# STM32F423xx register map
File version: 1.0
Registers are 32-bit, read-write, reset 0x0 unless marked. A register's access mark holds for its fields unless they carry their own. Offsets are from the block's base; [hi:lo] are bit positions; {n}, {i} and the like mark numbered series; 'fields as' and 'values as' point back to an identical list.

## AES — AES hardware accelerator
Base 0x50060000
0x00 CR — AES control register
0x04 SR — AES status register
0x08 DINR — AES data input register
0x0C DOUTR — AES data output register
{0x10+4i} KEYR{i} (i=0..3) — AES key register {i}
{0x20+4i} IVR{i} (i=0..3) — AES initialization vector register {i}
{0x20+4i} KEYR{i} (i=4..7) — AES key register {i}
{0x40+4i} SUSP{i}R (i=0..7) — AES Suspend register {i}

## RNG
Base 0x50060800
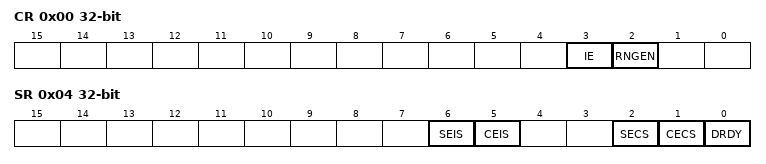
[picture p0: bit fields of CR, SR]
0x00 CR — RNG control register
  [3] IE, [2] RNGEN
0x04 SR — RNG status register
  [6] SEIS, [5] CEIS, [2] SECS, [1] CECS, [0] DRDY
0x08 DR — RNG data register

## FSMC_Bank1 — Flexible Static Memory Controller
Base 0xA0000000
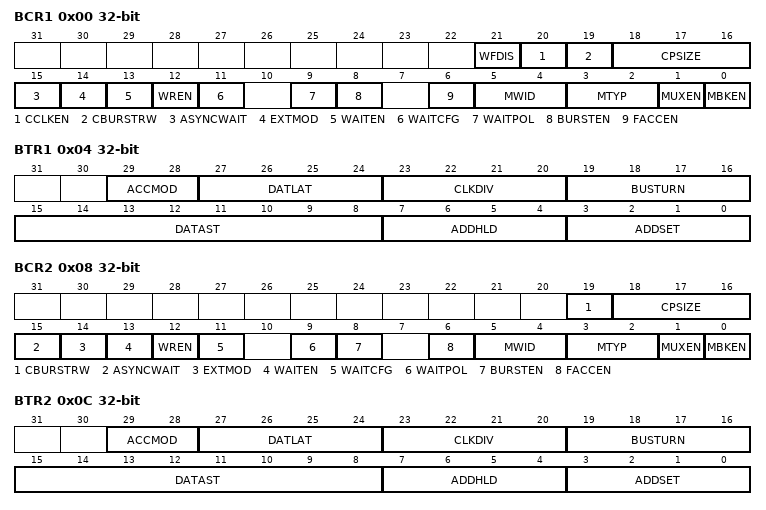
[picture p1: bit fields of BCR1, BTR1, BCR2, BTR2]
0x00 BCR1 — NOR/PSRAM chip-select control register(BCR) and chip-select timing register(BTR)
  [21] WFDIS — Write FIFO Disable
  [20] CCLKEN — Continuous clock enable
  [19] CBURSTRW — Write burst enable
  [18:16] CPSIZE — CRAM page size
  [15] ASYNCWAIT — Asynchronous wait
  [14] EXTMOD — Extended mode enable
  [13] WAITEN — Wait enable bit
  [12] WREN — Write enable bit
  [11] WAITCFG — Wait timing configuration
  [9] WAITPOL — Wait signal polarity bit
  [8] BURSTEN — Burst enable bit
  [6] FACCEN — Flash access enable
  [5:4] MWID — MWID[1:0] bits (Memory data bus width)
  [3:2] MTYP — MTYP[1:0] bits (Memory type)
  [1] MUXEN — Address/data multiplexing enable bit
  [0] MBKEN — Memory bank enable bit
0x04 BTR1 — NOR/PSRAM chip-select control register(BCR) and chip-select timing register(BTR)
  [29:28] ACCMOD — ACCMOD[1:0] bits (Access mode)
  [27:24] DATLAT — DATLA[3:0] bits (Data latency)
  [23:20] CLKDIV — CLKDIV[3:0] bits (Clock divide ratio)
  [19:16] BUSTURN — BUSTURN[3:0] bits (Bus turnaround phase duration)
  [15:8] DATAST — DATAST [7:0] bits (Data-phase duration)
  [7:4] ADDHLD — ADDHLD[3:0] bits (Address-hold phase duration)
  [3:0] ADDSET — ADDSET[3:0] bits (Address setup phase duration)
0x08 BCR2 — NOR/PSRAM chip-select control register(BCR) and chip-select timing register(BTR)
  [19] CBURSTRW — Write burst enable
  [18:16] CPSIZE — CRAM page size
  [15] ASYNCWAIT — Asynchronous wait
  [14] EXTMOD — Extended mode enable
  [13] WAITEN — Wait enable bit
  [12] WREN — Write enable bit
  [11] WAITCFG — Wait timing configuration
  [9] WAITPOL — Wait signal polarity bit
  [8] BURSTEN — Burst enable bit
  [6] FACCEN — Flash access enable
  [5:4] MWID — MWID[1:0] bits (Memory data bus width)
  [3:2] MTYP — MTYP[1:0] bits (Memory type)
  [1] MUXEN — Address/data multiplexing enable bit
  [0] MBKEN — Memory bank enable bit
0x0C BTR2 — NOR/PSRAM chip-select control register(BCR) and chip-select timing register(BTR)
  fields as BTR1
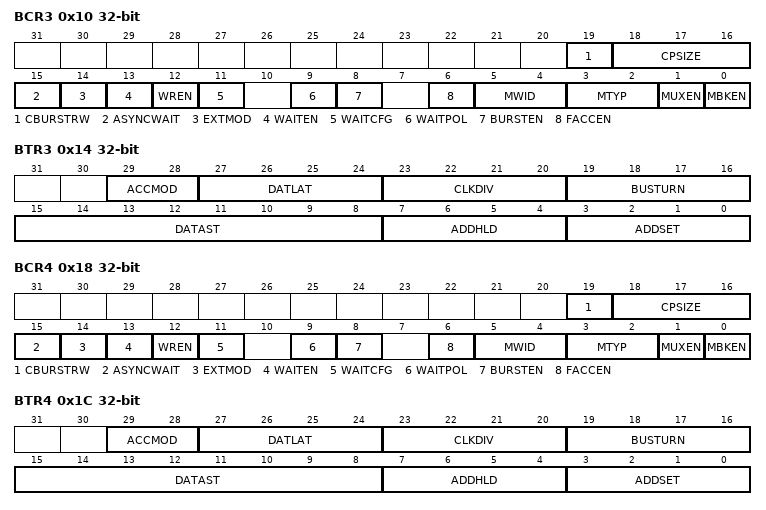
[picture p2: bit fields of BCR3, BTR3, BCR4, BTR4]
0x10 BCR3 — NOR/PSRAM chip-select control register(BCR) and chip-select timing register(BTR)
  fields as BCR2
0x14 BTR3 — NOR/PSRAM chip-select control register(BCR) and chip-select timing register(BTR)
  fields as BTR1
0x18 BCR4 — NOR/PSRAM chip-select control register(BCR) and chip-select timing register(BTR)
  fields as BCR2
0x1C BTR4 — NOR/PSRAM chip-select control register(BCR) and chip-select timing register(BTR)
  fields as BTR1

## FSMC_Bank1E — Flexible Static Memory Controller Bank1E
Base 0xA0000104
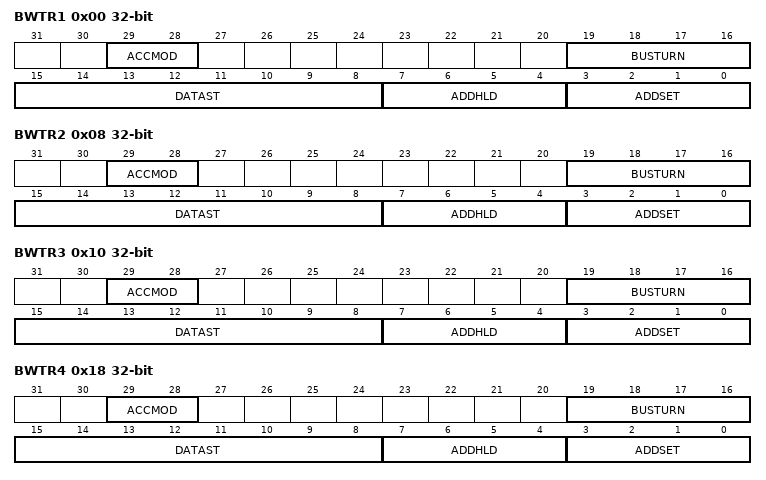
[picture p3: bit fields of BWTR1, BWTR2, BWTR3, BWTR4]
0x00 BWTR1 — NOR/PSRAM write timing registers
  [29:28] ACCMOD — ACCMOD[1:0] bits (Access mode)
  [19:16] BUSTURN — BUSTURN[3:0] bits (Bus turnaround duration)
  [15:8] DATAST — DATAST [7:0] bits (Data-phase duration)
  [7:4] ADDHLD — ADDHLD[3:0] bits (Address-hold phase duration)
  [3:0] ADDSET — ADDSET[3:0] bits (Address setup phase duration)
0x08 BWTR2 — NOR/PSRAM write timing registers
  fields as BWTR1
0x10 BWTR3 — NOR/PSRAM write timing registers
  fields as BWTR1
0x18 BWTR4 — NOR/PSRAM write timing registers
  [29:28] ACCMOD — ACCMOD[1:0] bits (Access mode)
  [19:16] BUSTURN — BUSTURN[3:0] bits (Bus turnaround duration)
  [15:8] DATAST — DATAST [3:0] bits (Data-phase duration)
  [7:4] ADDHLD — ADDHLD[3:0] bits (Address-hold phase duration)
  [3:0] ADDSET — ADDSET[3:0] bits (Address setup phase duration)

## QUADSPI — QUAD Serial Peripheral Interface
Base 0xA0001000
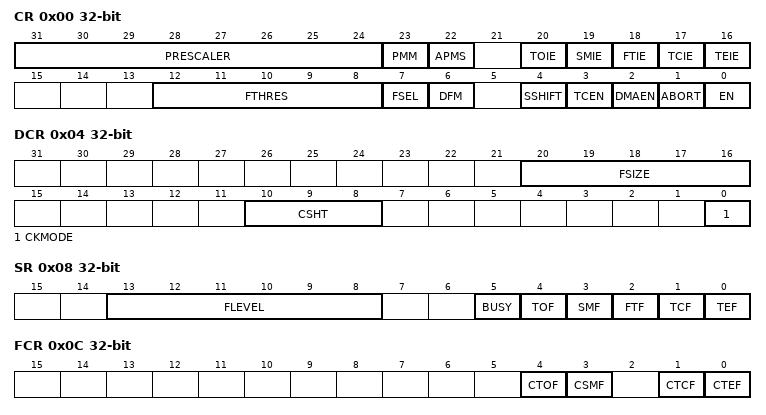
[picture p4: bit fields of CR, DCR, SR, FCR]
0x00 CR — QUADSPI Control register
  [31:24] PRESCALER — PRESCALER[7:0] Clock prescaler
  [23] PMM — Polling Match Mode
  [22] APMS — Bit 1
  [20] TOIE — TimeOut Interrupt Enable
  [19] SMIE — Status Match Interrupt Enable
  [18] FTIE — FIFO Threshold Interrupt Enable
  [17] TCIE — Transfer Complete Interrupt Enable
  [16] TEIE — Transfer Error Interrupt Enable
  [12:8] FTHRES — FTHRES[3:0] FIFO Level
  [7] FSEL — Flash Select
  [6] DFM — Dual Flash Mode
  [4] SSHIFT — SSHIFT Sample Shift
  [3] TCEN — Timeout Counter Enable
  [2] DMAEN — DMA Enable
  [1] ABORT — Abort request
  [0] EN — Enable
0x04 DCR — QUADSPI Device Configuration register
  [20:16] FSIZE — FSIZE[4:0]: Flash Size
  [10:8] CSHT — CSHT[2:0]: ChipSelect High Time
  [0] CKMODE — Mode 0 / Mode 3
0x08 SR — QUADSPI Status register
  [13:8] FLEVEL — FIFO Threshlod Flag
  [5] BUSY
  [4] TOF — Timeout Flag
  [3] SMF — Status Match Flag
  [2] FTF — FIFO Threshlod Flag
  [1] TCF — Transfer Complete Flag
  [0] TEF — Transfer Error Flag
0x0C FCR — QUADSPI Flag Clear register
  [4] CTOF — Clear Timeout Flag
  [3] CSMF — Clear Status Match Flag
  [1] CTCF — Clear Transfer Complete Flag
  [0] CTEF — Clear Transfer Error Flag
0x10 DLR — QUADSPI Data Length register
  [31:0] DL — DL[31:0]: Data Length
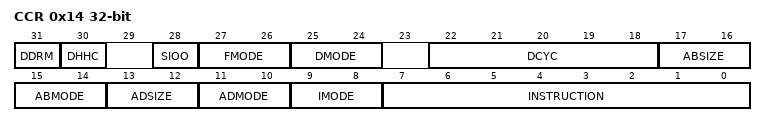
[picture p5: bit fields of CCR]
0x14 CCR — QUADSPI Communication Configuration register
  [31] DDRM — DDRM: Double Data Rate Mode
  [30] DHHC — DHHC: Delay Half Hclk Cycle
  [28] SIOO — SIOO: Send Instruction Only Once Mode
  [27:26] FMODE — FMODE[1:0]: Functional Mode
  [25:24] DMODE — DMODE[1:0]: Data Mode
  [22:18] DCYC — DCYC[4:0]: Dummy Cycles
  [17:16] ABSIZE — ABSIZE[1:0]: Instruction Mode
  [15:14] ABMODE — ABMODE[1:0]: Alternate Bytes Mode
  [13:12] ADSIZE — ADSIZE[1:0]: Address Size
  [11:10] ADMODE — ADMODE[1:0]: Address Mode
  [9:8] IMODE — IMODE[1:0]: Instruction Mode
  [7:0] INSTRUCTION — INSTRUCTION[7:0]: Instruction
0x18 AR — QUADSPI Address register
  [31:0] ADDRESS — ADDRESS[31:0]: Address
0x1C ABR — QUADSPI Alternate Bytes register
  [31:0] ALTERNATE — ALTERNATE[31:0]: Alternate Bytes
0x20 DR — QUADSPI Data register
  [31:0] DATA — DATA[31:0]: Data
0x24 PSMKR — QUADSPI Polling Status Mask register
  [31:0] MASK — MASK[31:0]: Status Mask
0x28 PSMAR — QUADSPI Polling Status Match register
  [31:0] MATCH — MATCH[31:0]: Status Match
0x2C PIR — QUADSPI Polling Interval register
  [15:0] INTERVAL — INTERVAL[15:0]: Polling Interval
0x30 LPTR — QUADSPI Low Power Timeout register
  [15:0] TIMEOUT — TIMEOUT[15:0]: Timeout period

## DBGMCU — Debug MCU
Base 0xE0042000
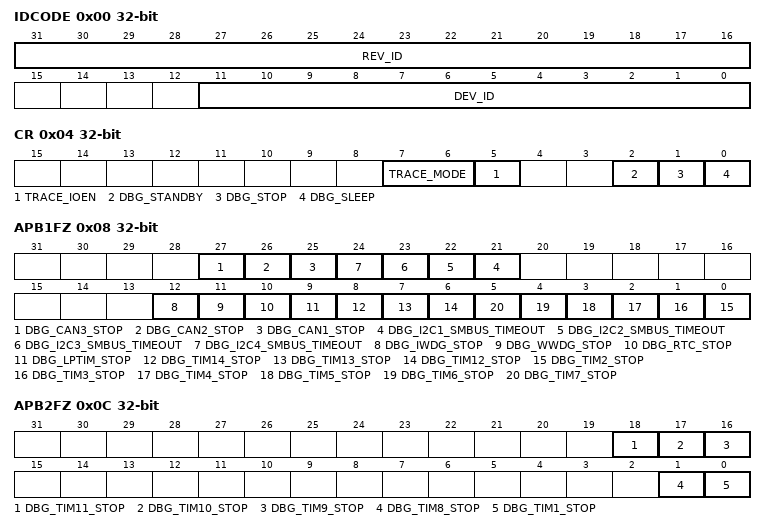
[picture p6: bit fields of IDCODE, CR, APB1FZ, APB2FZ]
0x00 IDCODE — MCU device ID code
  [31:16] REV_ID, [11:0] DEV_ID
0x04 CR — Debug MCU configuration register
  [7:6] TRACE_MODE, [5] TRACE_IOEN, [2] DBG_STANDBY, [1] DBG_STOP, [0] DBG_SLEEP
0x08 APB1FZ — Debug MCU APB1 freeze register
  [27] DBG_CAN3_STOP, [26] DBG_CAN2_STOP, [25] DBG_CAN1_STOP, [n+20] DBG_I2C{n}_SMBUS_TIMEOUT (n=1..4), [12] DBG_IWDG_STOP, [11] DBG_WWDG_STOP, [10] DBG_RTC_STOP, [9] DBG_LPTIM_STOP, [8] DBG_TIM14_STOP, [7] DBG_TIM13_STOP, [6] DBG_TIM12_STOP, [n-2] DBG_TIM{n}_STOP (n=2..7)
0x0C APB2FZ — Debug MCU APB2 freeze register
  [18] DBG_TIM11_STOP, [17] DBG_TIM10_STOP, [16] DBG_TIM9_STOP, [1] DBG_TIM8_STOP, [0] DBG_TIM1_STOP
